AUTOSAR XML (schema 4-0-3)
standard types defined: Boolean, UInt16, UInt32, UInt8
package /AUTOSAR_Platform/DataConstrs
  range DC_Boolean: raw 0..1
  range DC_UInt16: raw 0..65535
  range DC_UInt8: raw 0..255
package /PATAC/MSM/ComponentTypes
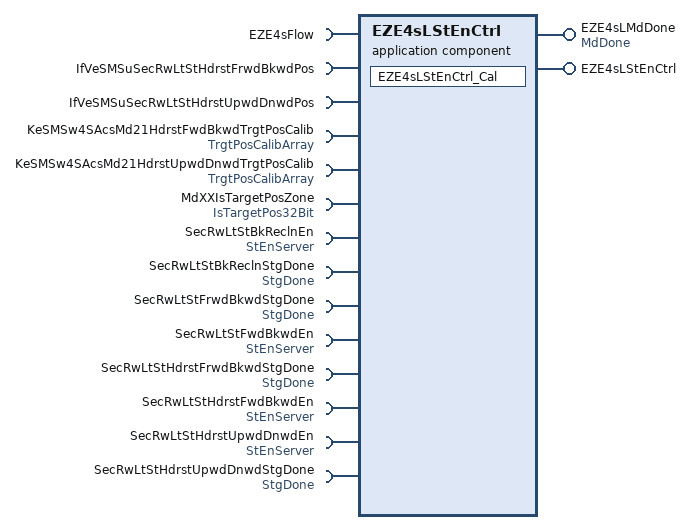
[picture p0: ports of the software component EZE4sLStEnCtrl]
  application sw component type EZE4sLStEnCtrl
    provide port EZE4sLMdDone: nonqueued-sender-com-spec{data-element=MdDone/Val, init-value=0}, provided-interface=MdDone
    provide port EZE4sLStEnCtrl: server-com-spec{operation=EZE4sLStEnCtrl/Cal, queue-length=1}, provided-interface=EZE4sLStEnCtrl
    14 x require port:
      EZE4sFlow: client-com-spec=EZE4sFlow/Cal, required-interface=EZE4sFlow
      IfVeSMSuSecRwLtStHdrstFrwdBkwdPos: nonqueued-receiver-com-spec{data-element=IfVeSMSuSecRwLtStHdrstFrwdBkwdPos/Val, filter=data-filter-type=ALWAYS, init-value=0}, required-interface=IfVeSMSuSecRwLtStHdrstFrwdBkwdPos
      IfVeSMSuSecRwLtStHdrstUpwdDnwdPos: nonqueued-receiver-com-spec{data-element=IfVeSMSuSecRwLtStHdrstUpwdDnwdPos/Val, filter=data-filter-type=ALWAYS, init-value=0}, required-interface=IfVeSMSuSecRwLtStHdrstUpwdDnwdPos
      KeSMSw4SAcsMd21HdrstFwdBkwdTrgtPosCalib: nonqueued-receiver-com-spec{data-element=TrgtPosArray, filter=data-filter-type=ALWAYS, init-value=[4095, 4095, 4095]}, required-interface=TrgtPosCalibArray
      KeSMSw4SAcsMd21HdrstUpwdDnwdTrgtPosCalib: nonqueued-receiver-com-spec{data-element=TrgtPosArray, filter=data-filter-type=ALWAYS, init-value=[4095, 4095, 4095]}, required-interface=TrgtPosCalibArray
      MdXXIsTargetPosZone: nonqueued-receiver-com-spec{data-element=IsTargetPos32Bit/Val, filter=data-filter-type=ALWAYS, init-value=0}, required-interface=IsTargetPos32Bit
      SecRwLtStBkReclnEn: required-com-specs=[Clear, Get, Set], required-interface=StEnServer
      SecRwLtStBkReclnStgDone: nonqueued-receiver-com-spec{data-element=StgDone/Val, filter=data-filter-type=ALWAYS, init-value=0}, required-interface=StgDone
      SecRwLtStFrwdBkwdStgDone: nonqueued-receiver-com-spec{data-element=StgDone/Val, filter=data-filter-type=ALWAYS, init-value=0}, required-interface=StgDone
      SecRwLtStFwdBkwdEn: required-com-specs=[Clear, Get, Set], required-interface=StEnServer
      SecRwLtStHdrstFrwdBkwdStgDone: nonqueued-receiver-com-spec{data-element=StgDone/Val, filter=data-filter-type=ALWAYS, init-value=0}, required-interface=StgDone
      SecRwLtStHdrstFwdBkwdEn: required-com-specs=[Clear, Get, Set], required-interface=StEnServer
      SecRwLtStHdrstUpwdDnwdEn: required-com-specs=[Clear, Get, Set], required-interface=StEnServer
      SecRwLtStHdrstUpwdDnwdStgDone: nonqueued-receiver-com-spec{data-element=StgDone/Val, filter=data-filter-type=ALWAYS, init-value=0}, required-interface=StgDone
    behavior EZE4sLStEnCtrl_InternalBehavior
      operation invoked event OIT_EZE4sLStEnCtrl_Cal_EZE4sLStEnCtrl_Cal: start-on-event=EZE4sLStEnCtrl_Cal, operation=EZE4sLStEnCtrl.Cal
      runnable EZE4sLStEnCtrl_Cal
        data-receive-point-by-arguments:
          9 x access:
            REC_IfVeSMSuSecRwLtStHdrstFrwdBkwdPos_Val: accessed-variable=IfVeSMSuSecRwLtStHdrstFrwdBkwdPos.Val
            REC_IfVeSMSuSecRwLtStHdrstUpwdDnwdPos_Val: accessed-variable=IfVeSMSuSecRwLtStHdrstUpwdDnwdPos.Val
            REC_KeSMSw4SAcsMd21HdrstFwdBkwdTrgtPosCalib_TrgtPosArray: accessed-variable=KeSMSw4SAcsMd21HdrstFwdBkwdTrgtPosCalib.TrgtPosArray
            REC_KeSMSw4SAcsMd21HdrstUpwdDnwdTrgtPosCalib_TrgtPosArray: accessed-variable=KeSMSw4SAcsMd21HdrstUpwdDnwdTrgtPosCalib.TrgtPosArray
            REC_MdXXIsTargetPosZone_Val: accessed-variable=MdXXIsTargetPosZone.Val
            REC_SecRwLtStBkReclnStgDone_Val: accessed-variable=SecRwLtStBkReclnStgDone.Val
            REC_SecRwLtStFrwdBkwdStgDone_Val: accessed-variable=SecRwLtStFrwdBkwdStgDone.Val
            REC_SecRwLtStHdrstFrwdBkwdStgDone_Val: accessed-variable=SecRwLtStHdrstFrwdBkwdStgDone.Val
            REC_SecRwLtStHdrstUpwdDnwdStgDone_Val: accessed-variable=SecRwLtStHdrstUpwdDnwdStgDone.Val
        data-send-points:
          access SEND_EZE4sLMdDone_Val: accessed-variable=EZE4sLMdDone.Val
        9 x sync call, all with timeout=0:
          SC_EZE4sFlow_Cal: operation=EZE4sFlow.Cal
          SC_SecRwLtStBkReclnEn_Clear: operation=SecRwLtStBkReclnEn.Clear
          SC_SecRwLtStBkReclnEn_Set: operation=SecRwLtStBkReclnEn.Set
          SC_SecRwLtStFwdBkwdEn_Clear: operation=SecRwLtStFwdBkwdEn.Clear
          SC_SecRwLtStFwdBkwdEn_Set: operation=SecRwLtStFwdBkwdEn.Set
          SC_SecRwLtStHdrstFwdBkwdEn_Clear: operation=SecRwLtStHdrstFwdBkwdEn.Clear
          SC_SecRwLtStHdrstFwdBkwdEn_Set: operation=SecRwLtStHdrstFwdBkwdEn.Set
          SC_SecRwLtStHdrstUpwdDnwdEn_Clear: operation=SecRwLtStHdrstUpwdDnwdEn.Clear
          SC_SecRwLtStHdrstUpwdDnwdEn_Set: operation=SecRwLtStHdrstUpwdDnwdEn.Set
  swc implementation EZE4sLStEnCtrl_Implementation: behavior=EZE4sLStEnCtrl_InternalBehavior
    code-descriptors:
      code Default: artifact-descriptors=autosar-engineering-object={short-label=Default, category=SWSRC}
package /PATAC/MSM/ModeAdjust/DataType
  impl type TrgtPosCalibArray: category=ARRAY, sw-calibration-access=READ-ONLY, type-emitter=RTE  # 0:pos 1:max 2:min
    element Element: array-size=3, array-size-semantics=FIXED-SIZE, implementation-data-type=UInt16, invalid-value=0
package /PATAC/MSM/ModeAdjust/PortInterface
  client server interface EZE4sFlow
    operation Cal
      9 x arg, all with server-argument-impl-policy=USE-ARGUMENT-TYPE:
        BkReclnStgDone: type=Implementation/Boolean, direction=IN
        HdrstUpwdDnwdStgDone: type=Implementation/Boolean, direction=IN
        HdrstFrwdBkwdStgDone: type=Implementation/Boolean, direction=IN
        SecRwStFrwdBkwdStgDone: type=DataTypes/Boolean, direction=IN
        Chkhdflg: type=Implementation/Boolean, direction=IN
        BkReclnEn: type=Implementation/Boolean, direction=OUT
        HdrstUpwdEn: type=Implementation/Boolean, direction=OUT
        HdrstFrwdEn: type=Implementation/Boolean, direction=OUT
        SecRwStFrwdBkwdEn: type=DataTypes/Boolean, direction=OUT
  client server interface EZE4sLStEnCtrl
    operation Cal
  client server interface StEnServer
    operation Clear
      arg data: type=UInt8, direction=IN, server-argument-impl-policy=USE-ARGUMENT-TYPE
    operation Get
      arg data: type=UInt32, direction=OUT, server-argument-impl-policy=USE-ARGUMENT-TYPE
    operation Set
      arg data: type=UInt8, direction=IN, server-argument-impl-policy=USE-ARGUMENT-TYPE
  4 x sender receiver interface:
    IsTargetPos32Bit: invalidation-policy{data-element=IsTargetPos32Bit/Val, handle-invalid=DONT-INVALIDATE}
      data Val: type=UInt32
    MdDone: invalidation-policy{data-element=MdDone/Val, handle-invalid=DONT-INVALIDATE}
      data Val: type=UInt8
    StgDone: invalidation-policy{data-element=StgDone/Val, handle-invalid=DONT-INVALIDATE}
      data Val: type=Implementation/Boolean
    TrgtPosCalibArray: invalidation-policy{data-element=TrgtPosArray, handle-invalid=DONT-INVALIDATE}
      data TrgtPosArray: type=TrgtPosCalibArray  # 0:Pos 1:Max 2:Min
package /PATAC/MSM/PortInterfaces
  sender receiver interface IfVeSMSuSecRwLtStHdrstFrwdBkwdPos: invalidation-policy{data-element=IfVeSMSuSecRwLtStHdrstFrwdBkwdPos/Val, handle-invalid=DONT-INVALIDATE}
    data Val: type=UInt16
  sender receiver interface IfVeSMSuSecRwLtStHdrstUpwdDnwdPos: invalidation-policy{data-element=IfVeSMSuSecRwLtStHdrstUpwdDnwdPos/Val, handle-invalid=DONT-INVALIDATE}
    data Val: type=UInt16
